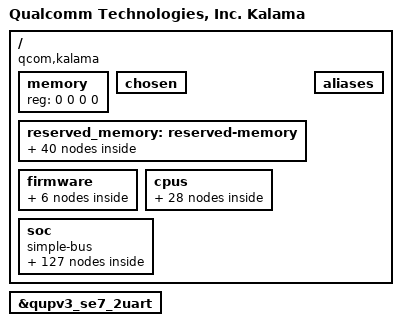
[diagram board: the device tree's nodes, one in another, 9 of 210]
#include <dt-bindings/interrupt-controller/arm-gic.h>
#include <dt-bindings/clock/qcom,camcc-kalama.h>
#include <dt-bindings/clock/qcom,dispcc-kalama.h>
#include <dt-bindings/clock/qcom,gcc-kalama.h>
#include <dt-bindings/clock/qcom,gpucc-kalama.h>
#include <dt-bindings/clock/qcom,rpmh.h>
#include <dt-bindings/clock/qcom,videocc-kalama.h>
#include <dt-bindings/regulator/qcom,rpmh-regulator-levels.h>
#include <dt-bindings/interconnect/qcom,kalama.h>
#include <dt-bindings/soc/qcom,ipcc.h>
#include <dt-bindings/soc/qcom,rpmh-rsc.h>

/ {
	model = "Qualcomm Technologies, Inc. Kalama";
	compatible = "qcom,kalama";
	qcom,msm-id = <519 0x10000>;
	interrupt-parent = <&intc>;

	#address-cells = <2>;
	#size-cells = <2>;
	memory { device_type = "memory"; reg = <0 0 0 0>; };


	chosen: chosen {
			bootargs = "nokaslr kpti=0 log_buf_len=256K swiotlb=noforce loop.max_part=7 fw_devlink.strict=1";
	 };

	reserved_memory: reserved-memory { };

	aliases {
		serial0 = &qupv3_se7_2uart;
		sdhc2 = &sdhc_2;
		ufshc1 = &ufshc_mem; /* Embedded UFS Slot */
	};

	firmware: firmware { };

	cpus {
		#address-cells = <2>;
		#size-cells = <0>;

		CPU0: cpu@0 {
			device_type = "cpu";
			compatible = "qcom,kryo";
			reg = <0x0 0x0>;
			enable-method = "psci";
			cpu-release-addr = <0x0 0xE3940000>;
			next-level-cache = <&L2_0>;
			L2_0: l2-cache {
			      compatible = "arm,arch-cache";
			      cache-level = <2>;
			      next-level-cache = <&L3_0>;

				L3_0: l3-cache {
					compatible = "arm,arch-cache";
					cache-level = <3>;
				};
			};
		};

		CPU1: cpu@100 {
			device_type = "cpu";
			compatible = "qcom,kryo";
			reg = <0x0 0x100>;
			enable-method = "psci";
			cpu-release-addr = <0x0 0xE3940000>;
			next-level-cache = <&L2_1>;
			L2_1: l2-cache {
			      compatible = "arm,arch-cache";
			      cache-level = <2>;
			      next-level-cache = <&L3_0>;
			};
		};

		CPU2: cpu@200 {
			device_type = "cpu";
			compatible = "qcom,kryo";
			reg = <0x0 0x200>;
			enable-method = "psci";
			cpu-release-addr = <0x0 0xE3940000>;
			next-level-cache = <&L2_1>;
		};

		CPU3: cpu@300 {
			device_type = "cpu";
			compatible = "qcom,kryo";
			reg = <0x0 0x300>;
			enable-method = "psci";
			cpu-release-addr = <0x0 0xE3940000>;
			next-level-cache = <&L2_3>;
			L2_3: l2-cache {
			      compatible = "arm,arch-cache";
			      cache-level = <2>;
			      next-level-cache = <&L3_0>;
			};
		};

		CPU4: cpu@400 {
			device_type = "cpu";
			compatible = "qcom,kryo";
			reg = <0x0 0x400>;
			enable-method = "psci";
			cpu-release-addr = <0x0 0xE3940000>;
			next-level-cache = <&L2_4>;
			L2_4: l2-cache {
			      compatible = "arm,arch-cache";
			      cache-level = <2>;
			      next-level-cache = <&L3_0>;

			};
		};

		CPU5: cpu@500 {
			device_type = "cpu";
			compatible = "qcom,kryo";
			reg = <0x0 0x500>;
			enable-method = "psci";
			cpu-release-addr = <0x0 0xE3940000>;
			next-level-cache = <&L2_5>;
			L2_5: l2-cache {
			      compatible = "arm,arch-cache";
			      cache-level = <2>;
			      next-level-cache = <&L3_0>;
			};
		};

		CPU6: cpu@600 {
			device_type = "cpu";
			compatible = "qcom,kryo";
			reg = <0x0 0x600>;
			enable-method = "psci";
			cpu-release-addr = <0x0 0xE3940000>;
			next-level-cache = <&L2_6>;
			L2_6: l2-cache {
			      compatible = "arm,arch-cache";
			      cache-level = <2>;
			      next-level-cache = <&L3_0>;
			};
		};

		CPU7: cpu@700 {
			device_type = "cpu";
			compatible = "qcom,kryo";
			reg = <0x0 0x700>;
			enable-method = "psci";
			cpu-release-addr = <0x0 0xE3940000>;
			next-level-cache = <&L2_7>;
			L2_7: l2-cache {
			      compatible = "arm,arch-cache";
			      cache-level = <2>;
			      next-level-cache = <&L3_0>;
			};
		};

		cpu-map {
			cluster0 {
				core0 {
					cpu = <&CPU0>;
				};

				core1 {
					cpu = <&CPU1>;
				};

				core2 {
					cpu = <&CPU2>;
				};
			};

			cluster1 {
				core0 {
					cpu = <&CPU3>;
				};

				core1 {
					cpu = <&CPU4>;
				};

				core2 {
					cpu = <&CPU5>;
				};

				core3 {
					cpu = <&CPU6>;
				};
			};

			cluster2 {
				core0 {
					cpu = <&CPU7>;
				};
			};
		};
	};

	soc: soc { };
};

&reserved_memory {
	#address-cells = <2>;
	#size-cells = <2>;
	ranges;

	hyp_qheebsp_mem: hyp_qheebsp_region@80000000 {
		no-map;
		reg = <0x0 0x80000000 0x0 0x200000>;
	};

	hyp_data_mem: hyp_data_region@80200000 {
		no-map;
		reg = <0x0 0x80200000 0x0 0x400000>;
	};

	hyp_rm_hypx_mem: hyp_rm_hypx_region@80600000 {
		no-map;
		reg = <0x0 0x80600000 0x0 0x200000>;
	};

	cpusys_vm_mem: cpusys_vm_region@80800000 {
		no-map;
		reg = <0x0 0x80800000 0x0 0x400000>;
	};

	hyp_tags_mem: hyp_tags_region@80c00000 {
		no-map;
		reg = <0x0 0x80c00000 0x0 0x340000>;
	};

	xbl_dt_log_mem: xbl_dt_log@81a00000 {
		no-map;
		reg = <0x0 0x81a00000 0x0 0x40000>;
	};

	xbl_ramdump_mem: xbl_ramdump_region@81a40000 {
		no-map;
		reg = <0x0 0x81a40000 0x0 0x1c0000>;
	};

	aop_image_mem: aop_image_region@81c00000 {
		no-map;
		reg = <0x0 0x81c00000 0x0 0x60000>;
	};

	aop_cmd_db_mem: aop_cmd_db_region@81c60000 {
		compatible = "qcom,cmd-db";
		no-map;
		reg = <0x0 0x81c60000 0x0 0x20000>;
	};

	aop_config_mem: aop_config_region@81c80000 {
		no-map;
		reg = <0x0 0x81c80000 0x0 0x20000>;
	};

	tme_crash_dump_mem: tme_crash_dump_region@81ca0000 {
		no-map;
		reg = <0x0 0x81ca0000 0x0 0x40000>;
	};

	tme_log_mem: tme_log_region@81ce0000 {
		no-map;
		reg = <0x0 0x81ce0000 0x0 0x4000>;
	};

	uefi_log_mem: uefi_log_region@81ce4000 {
		no-map;
		reg = <0x0 0x81ce4000 0x0 0x10000>;
	};

	/* secdata region can be reused by apps */

	smem_mem: smem_region@81d00000 {
		no-map;
		reg = <0x0 0x81d00000 0x0 0x200000>;
	};

	cpucp_fw_mem: cpucp_fw_region@81f00000 {
		no-map;
		reg = <0x0 0x81f00000 0x0 0x100000>;
	};

	global_sync_mem: global_sync_region@82000000 {
		no-map;
		reg = <0x0 0x82000000 0x0 0x100000>;
	};

	tz_stat_mem: tz_stat_region@82100000 {
		no-map;
		reg = <0x0 0x82100000 0x0 0x100000>;
	};

	llcc_lpi_mem: llcc_lpi_region@82200000 {
		no-map;
		reg = <0x0 0x82200000 0x0 0x600000>;
	};

	cdsp_secure_heap: cdsp_secure_heap_region@82800000 {
		no-map;
		reg = <0x0 0x82800000 0x0 0x4600000>;
	};

	camera_mem: camera_region@86e00000 {
		no-map;
		reg = <0x0 0x86e00000 0x0 0x500000>;
	};

	video_mem: video_region@87300000 {
		no-map;
		reg = <0x0 0x87300000 0x0 0x700000>;
	};

	adsp_slpi_mem: adsp_slpi_region@87a00000 {
		no-map;
		reg = <0x0 0x87a00000 0x0 0x3a00000>;
	};

	cdsp_mem: cdsp_region@8b400000 {
		no-map;
		reg = <0x0 0x8b400000 0x0 0x2000000>;
	};

	ipa_fw_mem: ipa_fw_region@8d400000 {
		no-map;
		reg = <0x0 0x8d400000 0x0 0x10000>;
	};

	ipa_gsi_mem: ipa_gsi_region@8d410000 {
		no-map;
		reg = <0x0 0x8d410000 0x0 0xa000>;
	};

	gpu_micro_code_mem: gpu_micro_code_region@8d41a000 {
		no-map;
		reg = <0x0 0x8d41a000 0x0 0x2000>;
	};

	spss_region_mem: spss_region_region@8d600000 {
		no-map;
		reg = <0x0 0x8d600000 0x0 0x180000>;
	};

	/* First part of the "SPU secure shared memory" region */
	spu_tz_shared_mem: spu_tz_shared_mem@8d780000 {
		no-map;
		reg = <0x0 0x8d780000 0x0 0x60000>;
	};

	/* Second part of the "SPU secure shared memory" region */
	spu_modem_shared_mem: spu_modem_shared_mem@8d7e0000 {
		no-map;
		reg = <0x0 0x8d7e0000 0x0 0x20000>;
	};

	mpss_mem: mpss_region@8d800000 {
		no-map;
		reg = <0x0 0x8d800000 0x0 0x13200000>;
	};

	cvp_mem: cvp_region@a0a00000 {
		no-map;
		reg = <0x0 0xa0a00000 0x0 0x700000>;
	};

	/* uefi region can be reused by apps */

	/* Linux kernel image is loaded at 0xa8000000 */

	xbl_sc_mem: xbl_sc_region@d8000000 {
		no-map;
		reg = <0x0 0xd8000000 0x0 0x40000>;
	};

	tz_reserved_mem: tz_reserved_region@d8040000 {
		no-map;
		reg = <0x0 0xd8040000 0x0 0xc0000>;
	};

	qtee_mem: qtee_region@d8100000 {
		no-map;
		reg = <0x0 0xd8100000 0x0 0x500000>;
	};

	trusted_apps_mem: trusted_apps_region@d8600000 {
		no-map;
		reg = <0x0 0xd8600000 0x0 0x8a00000>;
	};

	tz_tags_mem: tz_tags_region@e1000000 {
		no-map;
		reg = <0x0 0xe1000000 0x0 0x2700000>;
	};

	trust_ui_vm_mem: trust_ui_vm_region@f4400000 {
		no-map;
		reg = <0x0 0xf4400000 0x0 0x4400000>;
	};

	oem_vm_mem: oem_vm_region@f8800000 {
		no-map;
		reg = <0x0 0xf8800000 0x0 0x5000000>;
	};

	hyp_ext_tags_mem: hyp_ext_tags_region@fd800000 {
		no-map;
		reg = <0x0 0xfd800000 0x0 0x2800000>;
	};

	/* global autoconfigured region for contiguous allocations */
	system_cma: linux,cma {
		compatible = "shared-dma-pool";
		alloc-ranges = <0x0 0x00000000 0x0 0xffffffff>;
		reusable;
		alignment = <0x0 0x400000>;
		size = <0x0 0x2000000>;
		linux,cma-default;
	};
};

&soc {
	#address-cells = <1>;
	#size-cells = <1>;
	ranges = <0 0 0 0xffffffff>;
	compatible = "simple-bus";

	psci {
		compatible = "arm,psci-1.0";
		method = "smc";
	};

	intc: interrupt-controller@17100000 {
		compatible = "arm,gic-v3";
		#interrupt-cells = <3>;
		interrupt-controller;
		#redistributor-regions = <1>;
		redistributor-stride = <0x0 0x40000>;
		reg = <0x17100000 0x10000>,	/* GICD */
		      <0x17180000 0x200000>;	/* GICR * 8 */
		interrupts = <GIC_PPI 9 IRQ_TYPE_LEVEL_HIGH>;
	};

	apps_rsc: rsc@17a00000 {
		label = "apps_rsc";
		compatible = "qcom,rpmh-rsc";
		reg = <0x17a00000 0x10000>,
		      <0x17a10000 0x10000>,
		      <0x17a20000 0x10000>;
		reg-names = "drv-0", "drv-1", "drv-2";
		interrupts = <GIC_SPI 3 IRQ_TYPE_LEVEL_HIGH>,
			     <GIC_SPI 4 IRQ_TYPE_LEVEL_HIGH>,
			     <GIC_SPI 5 IRQ_TYPE_LEVEL_HIGH>;
		qcom,tcs-offset = <0xd00>;
		qcom,drv-id = <2>;
		qcom,tcs-config = <ACTIVE_TCS    2>,
				  <SLEEP_TCS     3>,
				  <WAKE_TCS      3>,
				  <CONTROL_TCS   0>,
				  <FAST_PATH_TCS 0>;
	};

	arch_timer: timer {
		compatible = "arm,armv8-timer";
		interrupts = <GIC_PPI 13 (GIC_CPU_MASK_SIMPLE(8) | IRQ_TYPE_LEVEL_LOW)>,
			     <GIC_PPI 14 (GIC_CPU_MASK_SIMPLE(8) | IRQ_TYPE_LEVEL_LOW)>,
			     <GIC_PPI 11 (GIC_CPU_MASK_SIMPLE(8) | IRQ_TYPE_LEVEL_LOW)>,
			     <GIC_PPI 12 (GIC_CPU_MASK_SIMPLE(8) | IRQ_TYPE_LEVEL_LOW)>;
		clock-frequency = <19200000>;
	};

	disp_rsc: rsc@af20000 {
		label = "disp_rsc";
		compatible = "qcom,rpmh-rsc";
		reg = <0xaf20000 0x10000>;
		reg-names = "drv-0";
		interrupts = <GIC_SPI 129 IRQ_TYPE_LEVEL_HIGH>;
		qcom,tcs-offset = <0x1c00>;
		qcom,drv-id = <0>;
		qcom,tcs-config = <ACTIVE_TCS    0>,
				  <SLEEP_TCS     1>,
				  <WAKE_TCS      1>,
				  <CONTROL_TCS   0>,
				  <FAST_PATH_TCS 0>;
	};

	memtimer: timer@17420000 {
		#address-cells = <1>;
		#size-cells = <1>;
		ranges;
		compatible = "arm,armv7-timer-mem";
		reg = <0x17420000 0x1000>;
		clock-frequency = <19200000>;

		frame@17421000 {
			frame-number = <0>;
			interrupts = <GIC_SPI 8 IRQ_TYPE_LEVEL_HIGH>,
				     <GIC_SPI 6 IRQ_TYPE_LEVEL_HIGH>;
			reg = <0x17421000 0x1000>,
			      <0x17422000 0x1000>;
		};

		frame@17423000 {
			frame-number = <1>;
			interrupts = <GIC_SPI 9 IRQ_TYPE_LEVEL_HIGH>;
			reg = <0x17423000 0x1000>;
			status = "disabled";
		};

		frame@17425000 {
			frame-number = <2>;
			interrupts = <GIC_SPI 10 IRQ_TYPE_LEVEL_HIGH>;
			reg = <0x17425000 0x1000>;
			status = "disabled";
		};

		frame@17427000 {
			frame-number = <3>;
			interrupts = <GIC_SPI 11 IRQ_TYPE_LEVEL_HIGH>;
			reg = <0x17427000 0x1000>;
			status = "disabled";
		};

		frame@17429000 {
			frame-number = <4>;
			interrupts = <GIC_SPI 12 IRQ_TYPE_LEVEL_HIGH>;
			reg = <0x17429000 0x1000>;
			status = "disabled";
		};

		frame@1742b000 {
			frame-number = <5>;
			interrupts = <GIC_SPI 13 IRQ_TYPE_LEVEL_HIGH>;
			reg = <0x1742b000 0x1000>;
			status = "disabled";
		};

		frame@1742d000 {
			frame-number = <6>;
			interrupts = <GIC_SPI 14 IRQ_TYPE_LEVEL_HIGH>;
			reg = <0x1742d000 0x1000>;
			status = "disabled";
		};
	};

	clk_virt: interconnect@0 {
		compatible = "qcom,kalama-clk_virt";
		qcom,stub;
		#interconnect-cells = <1>;
	};

	mc_virt: interconnect@1 {
		compatible = "qcom,kalama-mc_virt";
		qcom,stub;
		#interconnect-cells = <1>;
	};

	config_noc: interconnect@1600000 {
		compatible = "qcom,kalama-cnoc_cfg";
		qcom,stub;
		#interconnect-cells = <1>;
	};

	cnoc_main: interconnect@1500000 {
		compatible = "qcom,kalama-cnoc_main";
		qcom,stub;
		#interconnect-cells = <1>;
	};

	system_noc: interconnect@1680000 {
		compatible = "qcom,kalama-system_noc";
		qcom,stub;
		#interconnect-cells = <1>;
	};

	pcie_noc: interconnect@16c0000 {
		compatible = "qcom,kalama-pcie_anoc";
		qcom,stub;
		#interconnect-cells = <1>;
	};

	aggre1_noc: interconnect@16e0000 {
		compatible = "qcom,kalama-aggre1_noc";
		qcom,stub;
		#interconnect-cells = <1>;
	};

	aggre2_noc: interconnect@1700000 {
		compatible = "qcom,kalama-aggre2_noc";
		qcom,stub;
		#interconnect-cells = <1>;
	};

	mmss_noc: interconnect@1780000 {
		compatible = "qcom,kalama-mmss_noc";
		qcom,stub;
		#interconnect-cells = <1>;
	};

	gem_noc: interconnect@24100000 {
		compatible = "qcom,kalama-gem_noc";
		qcom,stub;
		#interconnect-cells = <1>;
	};

	nsp_noc: interconnect@320c0000 {
		compatible = "qcom,kalama-nsp_noc";
		qcom,stub;
		#interconnect-cells = <1>;
	};

	lpass_ag_noc: interconnect@7e40000 {
		compatible = "qcom,kalama-lpass_ag_noc";
		qcom,stub;
		#interconnect-cells = <1>;
	};

	lpass_lpiaon_noc: interconnect@7400000 {
		compatible = "qcom,kalama-lpass_lpiaon_noc";
		qcom,stub;
		#interconnect-cells = <1>;
	};

	lpass_lpicx_noc: interconnect@7430000 {
		compatible = "qcom,kalama-lpass_lpicx_noc";
		qcom,stub;
		#interconnect-cells = <1>;
	};

	pdc: interrupt-controller@b220000 {
		compatible = "qcom,kalama-pdc", "qcom,pdc";
		reg = <0xb220000 0x30000>, <0x174000f0 0x64>;
		qcom,pdc-ranges = <0 480 94>, <94 609 31>,
				  <125 63 1>, <126 716 12>;
		#interrupt-cells = <2>;
		interrupt-parent = <&intc>;
		interrupt-controller;
	};

	qcom,msm-imem@146aa000 {
		compatible = "qcom,msm-imem";
		reg = <0x146aa000 0x1000>;
		ranges = <0x0 0x146aa000 0x1000>;
		#address-cells = <1>;
		#size-cells = <1>;

		mem_dump_table@10 {
			compatible = "qcom,msm-imem-mem_dump_table";
			reg = <0x10 0x8>;
		};

		restart_reason@65c {
			compatible = "qcom,msm-imem-restart_reason";
			reg = <0x65c 0x4>;
		};

		dload_type@1c {
			compatible = "qcom,msm-imem-dload-type";
			reg = <0x1c 0x4>;
		};

		boot_stats@6b0 {
			compatible = "qcom,msm-imem-boot_stats";
			reg = <0x6b0 0x20>;
		};

		kaslr_offset@6d0 {
			compatible = "qcom,msm-imem-kaslr_offset";
			reg = <0x6d0 0xc>;
		};

		pil@94c {
			compatible = "qcom,pil-reloc-info";
			reg = <0x94c 0xc8>;
		};

		pil@6dc {
			compatible = "qcom,msm-imem-pil-disable-timeout";
			reg = <0x6dc 0x4>;
		};

		diag_dload@c8 {
			compatible = "qcom,msm-imem-diag-dload";
			reg = <0xc8 0xc8>;
		};
	};

	tlmm: pinctrl@f000000 {
		compatible = "qcom,kalama-pinctrl";
		reg = <0x0F000000 0x1000000>;
		interrupts = <GIC_SPI 208 IRQ_TYPE_LEVEL_HIGH>;
		gpio-controller;
		#gpio-cells = <2>;
		interrupt-controller;
		#interrupt-cells = <2>;
		wakeup-parent = <&pdc>;
	};

	dload_mode {
		compatible = "qcom,dload-mode";
	};

	qcom,secure-buffer {
		compatible = "qcom,secure-buffer";
		qcom,vmid-cp-camera-preview-ro;
	};

	qcom,mem-buf {
		compatible = "qcom,mem-buf";
		qcom,mem-buf-capabilities = "supplier";
		qcom,vmid = <3>;
	};

	qcom,mem-buf-msgq {
		compatible = "qcom,mem-buf-msgq";
	};

	clocks {
		xo_board: xo_board {
			compatible = "fixed-clock";
			clock-frequency = <76800000>;
			clock-output-names = "xo_board";
			#clock-cells = <0>;
		};

		sleep_clk: sleep_clk {
			compatible = "fixed-clock";
			clock-frequency = <32000>;
			clock-output-names = "sleep_clk";
			#clock-cells = <0>;
		};
	};

	cxo: bi_tcxo {
		compatible = "fixed-factor-clock";
		clocks = <&xo_board>;
		clock-mult = <1>;
		clock-div = <4>;
		#clock-cells = <0>;
		clock-output-names = "bi_tcxo";
	};

	cxo_a: bi_tcxo_ao {
		compatible = "fixed-factor-clock";
		clocks = <&xo_board>;
		clock-mult = <1>;
		clock-div = <4>;
		#clock-cells = <0>;
		clock-output-names = "bi_tcxo_ao";
	};

	rpmhcc: clock-controller {
		compatible = "fixed-clock";
		clock-output-names = "rpmh_clocks";
		clock-frequency = <19200000>;
		#clock-cells = <1>;
	};

	camcc: clock-controller@ade0000 {
		compatible = "qcom,kalama-camcc", "syscon";
		reg = <0xade0000 0x20000>;
		reg-name = "cc_base";
		vdd_mm-supply = <&VDD_MM_LEVEL>;
		vdd_mxa-supply = <&VDD_MXA_LEVEL>;
		vdd_mxc-supply = <&VDD_MXC_LEVEL>;
		clocks = <&rpmhcc RPMH_CXO_CLK>,
			 <&sleep_clk>,
			 <&gcc GCC_CAMERA_AHB_CLK>;
		clock-names = "bi_tcxo",
			      "sleep_clk",
			      "iface";
		#clock-cells = <1>;
		#reset-cells = <1>;
	};

	cpuss-sleep-stats@17800054 {
	      compatible = "qcom,cpuss-sleep-stats";
	      reg = <0x17800054 0x4>, <0x17810054 0x4>, <0x17820054 0x4>,
		    <0x17830054 0x4>, <0x17840054 0x4>, <0x17850054 0x4>,
		    <0x17860054 0x4>, <0x17870054 0x4>, <0x178a0098 0x4>,
		    <0x178c0000 0x10000>;
	      reg-names = "seq_lpm_cntr_cfg_cpu0", "seq_lpm_cntr_cfg_cpu1",
			  "seq_lpm_cntr_cfg_cpu2", "seq_lpm_cntr_cfg_cpu3",
			  "seq_lpm_cntr_cfg_cpu4", "seq_lpm_cntr_cfg_cpu5",
			  "seq_lpm_cntr_cfg_cpu6", "seq_lpm_cntr_cfg_cpu7",
			  "l3_seq_lpm_cntr_cfg", "apss_seq_mem_base";
	      num-cpus = <8>;
	};

	dispcc: clock-controller@af00000 {
		compatible = "qcom,kalama-dispcc", "syscon";
		reg = <0xaf00000 0x20000>;
		reg-name = "cc_base";
		vdd_mm-supply = <&VDD_MM_LEVEL>;
		vdd_mxa-supply = <&VDD_MXA_LEVEL>;
		clocks = <&rpmhcc RPMH_CXO_CLK>,
			 <&sleep_clk>,
			 <&gcc GCC_DISP_AHB_CLK>;
		clock-names = "bi_tcxo",
			      "sleep_clk",
			      "iface";
		#clock-cells = <1>;
		#reset-cells = <1>;
	};

	pcie_0_pipe_clk: pcie_0_pipe_clk {
		compatible = "fixed-clock";
		clock-frequency = <1000>;
		clock-output-names = "pcie_0_pipe_clk";
		#clock-cells = <0>;
	};

	pcie_1_phy_aux_clk: pcie_1_phy_aux_clk {
		compatible = "fixed-clock";
		clock-frequency = <1000>;
		clock-output-names = "pcie_1_phy_aux_clk";
		#clock-cells = <0>;
	};

	pcie_1_pipe_clk: pcie_1_pipe_clk {
		compatible = "fixed-clock";
		clock-frequency = <1000>;
		clock-output-names = "pcie_1_pipe_clk";
		#clock-cells = <0>;
	};

	ufs_phy_rx_symbol_0_clk: ufs_phy_rx_symbol_0_clk {
		compatible = "fixed-clock";
		clock-frequency = <1000>;
		clock-output-names = "ufs_phy_rx_symbol_0_clk";
		#clock-cells = <0>;
	};

	ufs_phy_rx_symbol_1_clk: ufs_phy_rx_symbol_1_clk {
		compatible = "fixed-clock";
		clock-frequency = <1000>;
		clock-output-names = "ufs_phy_rx_symbol_1_clk";
		#clock-cells = <0>;
	};

	ufs_phy_tx_symbol_0_clk: ufs_phy_tx_symbol_0_clk {
		compatible = "fixed-clock";
		clock-frequency = <1000>;
		clock-output-names = "ufs_phy_tx_symbol_0_clk";
		#clock-cells = <0>;
	};

	usb3_phy_wrapper_gcc_usb30_pipe_clk: usb3_phy_wrapper_gcc_usb30_pipe_clk {
		compatible = "fixed-clock";
		clock-frequency = <1000>;
		clock-output-names = "usb3_phy_wrapper_gcc_usb30_pipe_clk";
		#clock-cells = <0>;
	};

	gcc: clock-controller@100000 {
		compatible = "qcom,kalama-gcc", "syscon";
		reg = <0x100000 0x1f4200>;
		reg-name = "cc_base";
		vdd_cx-supply = <&VDD_CX_LEVEL>;
		vdd_mxa-supply = <&VDD_MXA_LEVEL>;
		clocks = <&rpmhcc RPMH_CXO_CLK>,
			 <&pcie_0_pipe_clk>,
			 <&pcie_1_phy_aux_clk>,
			 <&pcie_1_pipe_clk>,
			 <&sleep_clk>,
			 <&ufs_phy_rx_symbol_0_clk>,
			 <&ufs_phy_rx_symbol_1_clk>,
			 <&ufs_phy_tx_symbol_0_clk>,
			 <&usb3_phy_wrapper_gcc_usb30_pipe_clk>;
		clock-names = "bi_tcxo",
			      "pcie_0_pipe_clk",
			      "pcie_1_phy_aux_clk",
			      "pcie_1_pipe_clk",
			      "sleep_clk",
			      "ufs_phy_rx_symbol_0_clk",
			      "ufs_phy_rx_symbol_1_clk",
			      "ufs_phy_tx_symbol_0_clk",
			      "usb3_phy_wrapper_gcc_usb30_pipe_clk";
		#clock-cells = <1>;
		#reset-cells = <1>;
	};

	gpucc: clock-controller@3d90000 {
		compatible = "qcom,dummycc";
		clock-output-names = "gpucc_clocks";
		#clock-cells = <1>;
		#reset-cells = <1>;
	};

	videocc: clock-controller@abf0000 {
		compatible = "qcom,kalama-videocc", "syscon";
		reg = <0xabf0000 0x10000>;
		reg-name = "cc_base";
		vdd_mm-supply = <&VDD_MM_LEVEL>;
		vdd_mxc-supply = <&VDD_MXC_LEVEL>;
		clocks = <&rpmhcc RPMH_CXO_CLK>,
			 <&sleep_clk>,
			 <&gcc GCC_VIDEO_AHB_CLK>;
		clock-names = "bi_tcxo",
			      "sleep_clk",
			      "iface";
		#clock-cells = <1>;
		#reset-cells = <1>;
	};

	apsscc: syscon@17A80000 {
		compatible = "syscon";
		reg = <0x17A80000 0x21000>;
	};

	mccc: syscon@240ba000 {
		compatible = "syscon";
		reg = <0x240ba000 0x54>;
	};

	debugcc: qcom,cc-debug {
		compatible = "qcom,kalama-debugcc";
		qcom,gcc = <&gcc>;
		qcom,videocc = <&videocc>;
		qcom,dispcc = <&dispcc>;
		qcom,camcc = <&camcc>;
		qcom,apsscc = <&apsscc>;
		qcom,mccc = <&mccc>;
		clock-names = "xo_clk_src";
		clocks = <&rpmhcc RPMH_CXO_CLK>;
		#clock-cells = <1>;
	};

	/* CAM_CC GDSCs */
	cam_cc_bps_gdsc: qcom,gdsc@adf0004 {
		compatible = "qcom,gdsc";
		reg = <0xadf0004 0x4>;
		regulator-name = "cam_cc_bps_gdsc";
		clock-names = "ahb_clk";
		clocks = <&gcc GCC_CAMERA_AHB_CLK>;
		parent-supply = <&VDD_MM_MXC_VOTER_LEVEL>;
		qcom,gds-timeout = <500>;
		qcom,retain-regs;
	};

	cam_cc_ife_0_gdsc: qcom,gdsc@adf1004 {
		compatible = "qcom,gdsc";
		reg = <0xadf1004 0x4>;
		regulator-name = "cam_cc_ife_0_gdsc";
		clock-names = "ahb_clk";
		clocks = <&gcc GCC_CAMERA_AHB_CLK>;
		parent-supply = <&VDD_MM_MXC_VOTER_LEVEL>;
		qcom,gds-timeout = <500>;
		qcom,retain-regs;
	};

	cam_cc_ife_1_gdsc: qcom,gdsc@adf2004 {
		compatible = "qcom,gdsc";
		reg = <0xadf2004 0x4>;
		regulator-name = "cam_cc_ife_1_gdsc";
		clock-names = "ahb_clk";
		clocks = <&gcc GCC_CAMERA_AHB_CLK>;
		parent-supply = <&VDD_MM_MXC_VOTER_LEVEL>;
		qcom,gds-timeout = <500>;
		qcom,retain-regs;
	};

	cam_cc_ife_2_gdsc: qcom,gdsc@adf2294 {
		compatible = "qcom,gdsc";
		reg = <0xadf2294 0x4>;
		regulator-name = "cam_cc_ife_2_gdsc";
		clock-names = "ahb_clk";
		clocks = <&gcc GCC_CAMERA_AHB_CLK>;
		parent-supply = <&VDD_MM_MXC_VOTER_LEVEL>;
		qcom,gds-timeout = <500>;
		qcom,retain-regs;
	};

	cam_cc_ipe_0_gdsc: qcom,gdsc@adf03b8 {
		compatible = "qcom,gdsc";
		reg = <0xadf03b8 0x4>;
		regulator-name = "cam_cc_ipe_0_gdsc";
		clock-names = "ahb_clk";
		clocks = <&gcc GCC_CAMERA_AHB_CLK>;
		parent-supply = <&VDD_MM_MXC_VOTER_LEVEL>;
		qcom,gds-timeout = <500>;
		qcom,retain-regs;
	};

	cam_cc_sbi_gdsc: qcom,gdsc@adf052c {
		compatible = "qcom,gdsc";
		reg = <0xadf052c 0x4>;
		regulator-name = "cam_cc_sbi_gdsc";
		clock-names = "ahb_clk";
		clocks = <&gcc GCC_CAMERA_AHB_CLK>;
		parent-supply = <&VDD_MM_MXC_VOTER_LEVEL>;
		qcom,gds-timeout = <500>;
		qcom,retain-regs;
	};

	cam_cc_sfe_0_gdsc: qcom,gdsc@adf3280 {
		compatible = "qcom,gdsc";
		reg = <0xadf3280 0x4>;
		regulator-name = "cam_cc_sfe_0_gdsc";
		clock-names = "ahb_clk";
		clocks = <&gcc GCC_CAMERA_AHB_CLK>;
		parent-supply = <&VDD_MM_MXC_VOTER_LEVEL>;
		qcom,gds-timeout = <500>;
		qcom,retain-regs;
	};

	cam_cc_sfe_1_gdsc: qcom,gdsc@adf33e0 {
		compatible = "qcom,gdsc";
		reg = <0xadf33e0 0x4>;
		regulator-name = "cam_cc_sfe_1_gdsc";
		clock-names = "ahb_clk";
		clocks = <&gcc GCC_CAMERA_AHB_CLK>;
		parent-supply = <&VDD_MM_MXC_VOTER_LEVEL>;
		qcom,gds-timeout = <500>;
		qcom,retain-regs;
	};

	cam_cc_titan_top_gdsc: qcom,gdsc@adf4058 {
		compatible = "qcom,gdsc";
		reg = <0xadf4058 0x4>;
		regulator-name = "cam_cc_titan_top_gdsc";
		clock-names = "ahb_clk";
		clocks = <&gcc GCC_CAMERA_AHB_CLK>;
		parent-supply = <&VDD_MM_MXC_VOTER_LEVEL>;
		qcom,gds-timeout = <500>;
		qcom,retain-regs;
	};

	/* DISP_CC GDSCs */
	disp_cc_mdss_core_gdsc: qcom,gdsc@af09000 {
		compatible = "qcom,gdsc";
		reg = <0xaf09000 0x4>;
		regulator-name = "disp_cc_mdss_core_gdsc";
		clock-names = "ahb_clk";
		clocks = <&gcc GCC_DISP_AHB_CLK>;
		parent-supply = <&VDD_MM_LEVEL>;
		qcom,gds-timeout = <500>;
		qcom,retain-regs;
	};

	disp_cc_mdss_core_int2_gdsc: qcom,gdsc@af0b000 {
		compatible = "qcom,gdsc";
		reg = <0xaf0b000 0x4>;
		regulator-name = "disp_cc_mdss_core_int2_gdsc";
		clock-names = "ahb_clk";
		clocks = <&gcc GCC_DISP_AHB_CLK>;
		parent-supply = <&VDD_MM_LEVEL>;
		qcom,gds-timeout = <500>;
		qcom,retain-regs;
	};

	gcc_apcs_gdsc_vote_ctrl: syscon@152020{
		compatible = "syscon";
		reg = <0x152020 0x4>;
	};

	/* GCC GDSCs */
	gcc_pcie_0_gdsc: qcom,gdsc@16b004 {
		compatible = "qcom,gdsc";
		reg = <0x16b004 0x4>;
		regulator-name = "gcc_pcie_0_gdsc";
		parent-supply = <&VDD_CX_LEVEL>;
		clocks = <&gcc 0>;
		qcom,gds-timeout = <500>;
		qcom,retain-regs;
		qcom,no-status-check-on-disable;
		qcom,collapse-vote = <&gcc_apcs_gdsc_vote_ctrl 0>;
	};

	gcc_pcie_0_phy_gdsc: qcom,gdsc@16c000 {
		compatible = "qcom,gdsc";
		reg = <0x16c000 0x4>;
		regulator-name = "gcc_pcie_0_phy_gdsc";
		parent-supply = <&VDD_CX_LEVEL>;
		clocks = <&gcc 0>;
		qcom,gds-timeout = <500>;
		qcom,retain-regs;
		qcom,no-status-check-on-disable;
		qcom,collapse-vote = <&gcc_apcs_gdsc_vote_ctrl 3>;
	};

	gcc_pcie_1_gdsc: qcom,gdsc@18d004 {
		compatible = "qcom,gdsc";
		reg = <0x18d004 0x4>;
		regulator-name = "gcc_pcie_1_gdsc";
		parent-supply = <&VDD_CX_LEVEL>;
		clocks = <&gcc 0>;
		qcom,gds-timeout = <500>;
		qcom,retain-regs;
		qcom,no-status-check-on-disable;
		qcom,collapse-vote = <&gcc_apcs_gdsc_vote_ctrl 1>;
	};

	gcc_pcie_1_phy_gdsc: qcom,gdsc@18e000 {
		compatible = "qcom,gdsc";
		reg = <0x18e000 0x4>;
		regulator-name = "gcc_pcie_1_phy_gdsc";
		parent-supply = <&VDD_CX_LEVEL>;
		clocks = <&gcc 0>;
		qcom,gds-timeout = <500>;
		qcom,retain-regs;
		qcom,no-status-check-on-disable;
		qcom,collapse-vote = <&gcc_apcs_gdsc_vote_ctrl 4>;
	};

	gcc_ufs_mem_phy_gdsc: qcom,gdsc@19e000 {
		compatible = "qcom,gdsc";
		reg = <0x19e000 0x4>;
		regulator-name = "gcc_ufs_mem_phy_gdsc";
		clocks = <&gcc 0>;
		qcom,gds-timeout = <500>;
		parent-supply = <&VDD_CX_LEVEL>;
		qcom,retain-regs;
	};

	gcc_ufs_phy_gdsc: qcom,gdsc@177004 {
		compatible = "qcom,gdsc";
		reg = <0x177004 0x4>;
		regulator-name = "gcc_ufs_phy_gdsc";
		parent-supply = <&VDD_CX_LEVEL>;
		proxy-supply = <&gcc_ufs_phy_gdsc>;
		clocks = <&gcc 0>;
		qcom,gds-timeout = <500>;
		qcom,proxy-consumer-enable;
		qcom,retain-regs;
	};

	gcc_usb30_prim_gdsc: qcom,gdsc@139004 {
		compatible = "qcom,gdsc";
		reg = <0x139004 0x4>;
		regulator-name = "gcc_usb30_prim_gdsc";
		proxy-supply = <&gcc_usb30_prim_gdsc>;
		clocks = <&gcc 0>;
		qcom,gds-timeout = <500>;
		qcom,proxy-consumer-enable;
		qcom,retain-regs;
	};

	gcc_usb3_phy_gdsc: qcom,gdsc@150018 {
		compatible = "qcom,gdsc";
		reg = <0x150018 0x4>;
		regulator-name = "gcc_usb3_phy_gdsc";
		clocks = <&gcc 0>;
		qcom,gds-timeout = <500>;
		parent-supply = <&VDD_CX_LEVEL>;
		qcom,retain-regs;
	};

	/* GPU_CC GDSCs */
	gpu_cc_cx_gdsc: qcom,gdsc@3d99108 {
		compatible = "qcom,stub-regulator";
		regulator-name = "gpu_cc_cx_gdsc";
	};

	gpu_cc_gx_gdsc: qcom,gdsc@3d9905c {
		compatible = "qcom,stub-regulator";
		regulator-name = "gpu_cc_gx_gdsc";
	};

	/* VIDEO_CC GDSCs */
	video_cc_mvs0_gdsc: qcom,gdsc@abf80a4 {
		compatible = "qcom,gdsc";
		reg = <0xabf80a4 0x4>;
		regulator-name = "video_cc_mvs0_gdsc";
		parent-supply = <&video_cc_mvs0c_gdsc>;
		clock-names = "ahb_clk";
		clocks = <&gcc GCC_VIDEO_AHB_CLK>;
		qcom,gds-timeout = <500>;
		qcom,support-hw-trigger;
		qcom,retain-regs;
	};

	video_cc_mvs0c_gdsc: qcom,gdsc@abf804c {
		compatible = "qcom,gdsc";
		reg = <0xabf804c 0x4>;
		regulator-name = "video_cc_mvs0c_gdsc";
		clock-names = "ahb_clk";
		clocks = <&gcc GCC_VIDEO_AHB_CLK>;
		parent-supply = <&VDD_MM_MXC_VOTER_LEVEL>;
		qcom,gds-timeout = <500>;
		qcom,retain-regs;
	};

	video_cc_mvs1_gdsc: qcom,gdsc@abf80cc {
		compatible = "qcom,gdsc";
		reg = <0xabf80cc 0x4>;
		regulator-name = "video_cc_mvs1_gdsc";
		parent-supply = <&video_cc_mvs1c_gdsc>;
		clock-names = "ahb_clk";
		clocks = <&gcc GCC_VIDEO_AHB_CLK>;
		qcom,gds-timeout = <500>;
		qcom,support-hw-trigger;
		qcom,retain-regs;	};

	video_cc_mvs1c_gdsc: qcom,gdsc@abf8078 {
		compatible = "qcom,gdsc";
		reg = <0xabf8078 0x4>;
		regulator-name = "video_cc_mvs1c_gdsc";
		parent-supply = <&VDD_MM_MXC_VOTER_LEVEL>;
		clock-names = "ahb_clk";
		clocks = <&gcc GCC_VIDEO_AHB_CLK>;
		qcom,gds-timeout = <500>;
		qcom,retain-regs;
	};

	sdhc_2: sdhci@8804000 {
		status = "disabled";

		compatible = "qcom,sdhci-msm-v5";
		reg = <0x08804000 0x1000>;
		reg-names = "hc_mem";

		interrupts = <GIC_SPI 207 IRQ_TYPE_LEVEL_HIGH>,
				<GIC_SPI 223 IRQ_TYPE_LEVEL_HIGH>;
		interrupt-names = "hc_irq", "pwr_irq";

		bus-width = <4>;
		no-sdio;
		no-mmc;
		qcom,restore-after-cx-collapse;

		clocks = <&gcc GCC_SDCC2_AHB_CLK>,
			<&gcc GCC_SDCC2_APPS_CLK>;
		clock-names = "iface", "core";

		/* DLL HSR settings. Refer go/hsr - <Target> DLL settings */
		qcom,dll-hsr-list = <0x0007642C 0xA800 0x10
					0x2C010800 0x80040868>;

		iommus = <&apps_smmu 0x540 0x0>;
		dma-coherent;
	};

	ufsphy_mem: ufsphy_mem@1d80000 {
		reg = <0x1d80000 0x1934>;
		reg-names = "phy_mem";
		#phy-cells = <0>;

		lanes-per-direction = <2>;
		clock-names = "ref_clk_src",
			"ref_aux_clk";
		clocks = <&rpmhcc RPMH_CXO_CLK>,
			<&gcc GCC_UFS_PHY_PHY_AUX_CLK>;
		resets = <&ufshc_mem 0>;
		status = "disabled";
	};

	ufshc_mem: ufshc@1d84000 {
		compatible = "qcom,ufshc";
		reg = <0x1d84000 0x3000>,
		      <0x1d88000 0x8000>;
		reg-names = "ufs_mem", "ufs_ice";
		interrupts = <GIC_SPI 265 IRQ_TYPE_LEVEL_HIGH>;
		phys = <&ufsphy_mem>;
		phy-names = "ufsphy";
		#reset-cells = <1>;

		lanes-per-direction = <2>;
		dev-ref-clk-freq = <0>; /* 19.2 MHz */
		clock-names =
			"core_clk",
			"bus_aggr_clk",
			"iface_clk",
			"core_clk_unipro",
			"core_clk_ice",
			"ref_clk",
			"tx_lane0_sync_clk",
			"rx_lane0_sync_clk",
			"rx_lane1_sync_clk";
		clocks =
			<&gcc GCC_UFS_PHY_AXI_CLK>,
			<&gcc GCC_AGGRE_UFS_PHY_AXI_CLK>,
			<&gcc GCC_UFS_PHY_AHB_CLK>,
			<&gcc GCC_UFS_PHY_UNIPRO_CORE_CLK>,
			<&gcc GCC_UFS_PHY_ICE_CORE_CLK>,
			<&rpmhcc RPMH_CXO_CLK>,
			<&gcc GCC_UFS_PHY_TX_SYMBOL_0_CLK>,
			<&gcc GCC_UFS_PHY_RX_SYMBOL_0_CLK>,
			<&gcc GCC_UFS_PHY_RX_SYMBOL_1_CLK>;
		freq-table-hz =
			<75000000 300000000>,
			<0 0>,
			<0 0>,
			<75000000 300000000>,
			<75000000 300000000>,
			<0 0>,
			<0 0>,
			<0 0>,
			<0 0>;

		iommus = <&apps_smmu 0x60 0x0>;
		dma-coherent;

		status = "disabled";
	};

	tcsr_mutex_block: syscon@1f40000 {
		compatible = "syscon";
		reg = <0x1f40000 0x20000>;
	};

	tcsr_mutex: hwlock {
		compatible = "qcom,tcsr-mutex";
		syscon = <&tcsr_mutex_block 0 0x1000>;
		#hwlock-cells = <1>;
	};

	smem: qcom,smem {
		compatible = "qcom,smem";
		memory-region = <&smem_mem>;
		depends-on-supply = <&tcsr_mutex>;
		hwlocks = <&tcsr_mutex 3>;
	};

	aoss_qmp: power-controller@c300000 {
		compatible = "qcom,kalama-aoss-qmp";
		reg = <0xc300000 0x400>;
		interrupt-parent = <&ipcc_mproc>;
		interrupts = <IPCC_CLIENT_AOP
			      IPCC_MPROC_SIGNAL_GLINK_QMP
			      IRQ_TYPE_EDGE_RISING>;
		mboxes = <&ipcc_mproc IPCC_CLIENT_AOP
			  IPCC_MPROC_SIGNAL_GLINK_QMP>;

		#power-domain-cells = <1>;
		#clock-cells = <0>;
	};

	qmp_aop: qcom,qmp-aop {
		compatible = "qcom,qmp-mbox";
		qcom,qmp = <&aoss_qmp>;
		label = "aop";
		#mbox-cells = <1>;
	};

	qmp_tme: qcom,qmp-tme {
		compatible = "qcom,qmp-mbox";
		qcom,remote-pid = <14>;
		mboxes = <&ipcc_mproc IPCC_CLIENT_TME
			  IPCC_MPROC_SIGNAL_GLINK_QMP>;
		mbox-names = "tme_qmp";
		interrupt-parent = <&ipcc_mproc>;
		interrupts = <IPCC_CLIENT_TME
			      IPCC_MPROC_SIGNAL_GLINK_QMP
			      IRQ_TYPE_EDGE_RISING>;

		label = "tme";
		qcom,early-boot;
		priority = <0>;
		mbox-desc-offset = <0x0>;
		#mbox-cells = <1>;
	};

	qcom,smp2p-adsp {
		compatible = "qcom,smp2p";
		qcom,smem = <443>, <429>;
		interrupt-parent = <&ipcc_mproc>;
		interrupts = <IPCC_CLIENT_LPASS IPCC_MPROC_SIGNAL_SMP2P
			      IRQ_TYPE_EDGE_RISING>;
		mboxes = <&ipcc_mproc IPCC_CLIENT_LPASS
			  IPCC_MPROC_SIGNAL_SMP2P>;
		qcom,local-pid = <0>;
		qcom,remote-pid = <2>;

		adsp_smp2p_out: master-kernel {
			qcom,entry-name = "master-kernel";
			#qcom,smem-state-cells = <1>;
		};

		adsp_smp2p_in: slave-kernel {
			qcom,entry-name = "slave-kernel";
			interrupt-controller;
			#interrupt-cells = <2>;
		};

		sleepstate_smp2p_out: sleepstate-out {
			qcom,entry-name = "sleepstate";
			#qcom,smem-state-cells = <1>;
		};

		sleepstate_smp2p_in: qcom,sleepstate-in {
			qcom,entry-name = "sleepstate_see";
			interrupt-controller;
			#interrupt-cells = <2>;
		};

		smp2p_rdbg2_out: qcom,smp2p-rdbg2-out {
			qcom,entry-name = "rdbg";
			#qcom,smem-state-cells = <1>;
		};

		smp2p_rdbg2_in: qcom,smp2p-rdbg2-in {
			qcom,entry-name = "rdbg";
			interrupt-controller;
			#interrupt-cells = <2>;
		};
	};

	qcom,smp2p-cdsp {
		compatible = "qcom,smp2p";
		qcom,smem = <94>, <432>;
		interrupt-parent = <&ipcc_mproc>;
		interrupts = <IPCC_CLIENT_CDSP IPCC_MPROC_SIGNAL_SMP2P
			      IRQ_TYPE_EDGE_RISING>;
		mboxes = <&ipcc_mproc IPCC_CLIENT_CDSP IPCC_MPROC_SIGNAL_SMP2P>;
		qcom,local-pid = <0>;
		qcom,remote-pid = <5>;

		cdsp_smp2p_out: master-kernel {
			qcom,entry-name = "master-kernel";
			#qcom,smem-state-cells = <1>;
		};

		cdsp_smp2p_in: slave-kernel {
			qcom,entry-name = "slave-kernel";
			interrupt-controller;
			#interrupt-cells = <2>;
		};

		smp2p_rdbg5_out: qcom,smp2p-rdbg5-out {
			qcom,entry-name = "rdbg";
			#qcom,smem-state-cells = <1>;
		};

		smp2p_rdbg5_in: qcom,smp2p-rdbg5-in {
			qcom,entry-name = "rdbg";
			interrupt-controller;
			#interrupt-cells = <2>;
		};
	};

	qcom,smp2p-modem {
		compatible = "qcom,smp2p";
		qcom,smem = <435>, <428>;
		interrupt-parent = <&ipcc_mproc>;
		interrupts = <IPCC_CLIENT_MPSS IPCC_MPROC_SIGNAL_SMP2P
			      IRQ_TYPE_EDGE_RISING>;
		mboxes = <&ipcc_mproc IPCC_CLIENT_MPSS IPCC_MPROC_SIGNAL_SMP2P>;
		qcom,local-pid = <0>;
		qcom,remote-pid = <1>;

		modem_smp2p_out: master-kernel {
			qcom,entry-name = "master-kernel";
			#qcom,smem-state-cells = <1>;
		};

		modem_smp2p_in: slave-kernel {
			qcom,entry-name = "slave-kernel";
			interrupt-controller;
			#interrupt-cells = <2>;
		};

		smp2p_ipa_1_out: qcom,smp2p-ipa-1-out {
			qcom,entry-name = "ipa";
			#qcom,smem-state-cells = <1>;
		};

		/* ipa - inbound entry from mss */
		smp2p_ipa_1_in: qcom,smp2p-ipa-1-in {
			qcom,entry-name = "ipa";
			interrupt-controller;
			#interrupt-cells = <2>;
		};
	};

	qcom,smp2p_sleepstate {
		compatible = "qcom,smp2p-sleepstate";
		qcom,smem-states = <&sleepstate_smp2p_out 0>;
		interrupt-parent = <&sleepstate_smp2p_in>;
		interrupts = <0 0>;
		interrupt-names = "smp2p-sleepstate-in";
	};

	qcom,qsee_ipc_irq_bridge {
		compatible = "qcom,qsee-ipc-irq-bridge";

		qcom,qsee-ipc-irq-spss {
			qcom,dev-name = "qsee_ipc_irq_spss";
			interrupt-parent = <&ipcc_mproc>;
			interrupts = <IPCC_CLIENT_SPSS
				      IPCC_MPROC_SIGNAL_TZ
				      IRQ_TYPE_EDGE_RISING>;
			label = "spss";
		};
	};

	soc-sleep-stats@c3f0000 {
		compatible = "qcom,rpmh-sleep-stats";
		reg = <0xc3f0000 0x400>;
		ss-name = "modem", "adsp", "adsp_island",
			  "cdsp", "slpi", "slpi_island",
			  "apss";
	};

	subsystem-sleep-stats@c3f0000 {
		compatible = "qcom,subsystem-sleep-stats";
		reg = <0xc3f0000 0x400>;
	};

	tcsr: syscon@1fc0000 {
	      compatible = "syscon";
	      reg = <0x1fc0000 0x30000>;
	};

	qcom,mpm2-sleep-counter@c221000 {
		compatible = "qcom,mpm2-sleep-counter";
		reg = <0xc221000 0x1000>;
		clock-frequency = <32768>;
	};

	cache-controller@25000000 {
		compatible = "qcom,kalama-llcc", "qcom,llcc-v41";
		reg = <0x25000000 0x800000> , <0x25800000 0x200000>;
		reg-names = "llcc_base", "llcc_broadcast_base";
		interrupts = <GIC_SPI 266 IRQ_TYPE_LEVEL_HIGH>;
		cap-based-alloc-and-pwr-collapse;
	};

	qcom,chd {
		compatible = "qcom,core-hang-detect";
		label = "core";
		qcom,threshold-arr = <0x17800058 0x17810058 0x17820058 0x17830058
			0x17840058 0x17850058 0x17860058 0x17870058>;
		qcom,config-arr = <0x17800060 0x17810060 0x17820060 0x17830060
			0x17840060 0x17850060 0x17860060 0x17870060>;
	};

	eud: qcom,msm-eud@88e0000 {
		compatible = "qcom,msm-eud";
		interrupt-names = "eud_irq";
		interrupt-parent = <&pdc>;
		interrupts = <11 IRQ_TYPE_LEVEL_HIGH>;
		reg = <0x088E0000 0x2000>,
			<0x088E2000 0x1000>;
		reg-names = "eud_base", "eud_mode_mgr2";
		qcom,secure-eud-en;
		status = "ok";
	};

	ipcc_mproc: qcom,ipcc@408000 {
		compatible = "qcom,ipcc";
		reg = <0x408000 0x1000>;
		interrupts = <GIC_SPI 229 IRQ_TYPE_LEVEL_HIGH>;
		interrupt-controller;
		#interrupt-cells = <3>;
		#mbox-cells = <2>;
	};
};

&firmware {
	qcom_scm {
		compatible = "qcom,scm";
		qcom,dload-mode = <&tcsr 0x13000>;
	};

	android {
		compatible = "android,firmware";
		vbmeta {
			compatible = "android,vbmeta";
			parts = "vbmeta,boot,system,vendor,dtbo,recovery";
		};

		fstab {
			compatible = "android,fstab";
			vendor {
				compatible = "android,vendor";
				dev = "/dev/block/platform/soc/1d84000.ufshc/by-name/vendor";
				type = "ext4";
				mnt_flags = "ro,barrier=1,discard";
				fsmgr_flags = "wait,slotselect,avb";
				status = "ok";
			};
		};
	};

	qtee_shmbridge {
		compatible = "qcom,tee-shared-memory-bridge";
	};
};

#include "kalama-pinctrl.dtsi"
#include "msm-arm-smmu-kalama.dtsi"
#include "kalama-dma-heaps.dtsi"
#include "kalama-regulators.dtsi"
#include "kalama-qupv3.dtsi"
#include "kalama-usb.dtsi"

&qupv3_se7_2uart {
	status = "ok";
};
